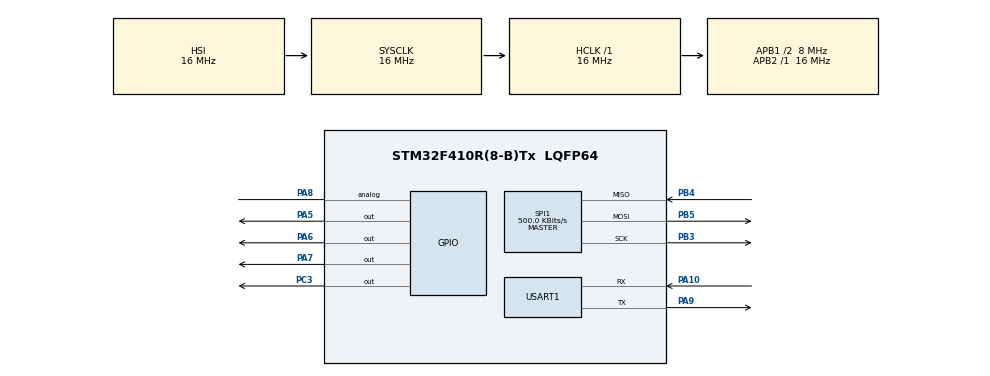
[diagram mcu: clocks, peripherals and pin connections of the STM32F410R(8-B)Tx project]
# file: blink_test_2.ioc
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Mcu.Family=STM32F4
Mcu.Name=STM32F410R(8-B)Tx
Mcu.Package=LQFP64
NVIC.PriorityGroup=NVIC_PRIORITYGROUP_4
NVIC.USART1_IRQn=true\:0\:0\:false\:false\:true\:true
PA10.Mode=Asynchronous
PA10.Signal=USART1_RX
PA5.Signal=GPIO_Output
PA6.Signal=GPIO_Output
PA7.Signal=GPIO_Output
PA8.Signal=GPIO_Analog
PA9.Mode=Asynchronous
PA9.Signal=USART1_TX
PB3.Mode=Full_Duplex_Master
PB3.Signal=SPI1_SCK
PB4.Mode=Full_Duplex_Master
PB4.Signal=SPI1_MISO
PB5.Mode=Full_Duplex_Master
PB5.Signal=SPI1_MOSI
PC3.Signal=GPIO_Output
ProjectManager.HeapSize=0x200
ProjectManager.StackSize=0x400
ProjectManager.TargetToolchain=MDK-ARM V5
RCC.48MHZClocksFreq_Value=84000000
RCC.AHBFreq_Value=16000000
RCC.APB1CLKDivider=RCC_HCLK_DIV2
RCC.APB1Freq_Value=8000000
RCC.APB1TimFreq_Value=16000000
RCC.APB2Freq_Value=16000000
RCC.APB2TimFreq_Value=16000000
RCC.CortexFreq_Value=16000000
RCC.FLatency-AdvancedSettings=FLASH_LATENCY_0
RCC.HCLKFreq_Value=16000000
RCC.HSE_VALUE=8000000
RCC.HSI_VALUE=16000000
RCC.LSE_VALUE=32768
RCC.PLLN=336
RCC.PLLP=RCC_PLLP_DIV4
RCC.SYSCLKFreq_VALUE=16000000
RCC.VCOOutputFreq_Value=336000000
SPI1.BaudRatePrescaler=SPI_BAUDRATEPRESCALER_32
SPI1.CalculateBaudRate=500.0 KBits/s
SPI1.Direction=SPI_DIRECTION_2LINES
SPI1.Mode=SPI_MODE_MASTER
SPI1.VirtualType=VM_MASTER
USART1.VirtualMode=VM_ASYNC
board=NUCLEO-F410RB

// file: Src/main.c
/**
  ******************************************************************************
  * @file           : main.c
  * @brief          : Main program body
  ******************************************************************************
  ** This notice applies to any and all portions of this file
  * that are not between comment pairs USER CODE BEGIN and
  * USER CODE END. Other portions of this file, whether
  * inserted by the user or by software development tools
  * are owned by their respective copyright owners.
  *
  * COPYRIGHT(c) 2018 STMicroelectronics
  *
  * Redistribution and use in source and binary forms, with or without modification,
  * are permitted provided that the following conditions are met:
  *   1. Redistributions of source code must retain the above copyright notice,
  *      this list of conditions and the following disclaimer.
  *   2. Redistributions in binary form must reproduce the above copyright notice,
  *      this list of conditions and the following disclaimer in the documentation
  *      and/or other materials provided with the distribution.
  *   3. Neither the name of STMicroelectronics nor the names of its contributors
  *      may be used to endorse or promote products derived from this software
  *      without specific prior written permission.
  *
  * THIS SOFTWARE IS PROVIDED BY THE COPYRIGHT HOLDERS AND CONTRIBUTORS "AS IS"
  * AND ANY EXPRESS OR IMPLIED WARRANTIES, INCLUDING, BUT NOT LIMITED TO, THE
  * IMPLIED WARRANTIES OF MERCHANTABILITY AND FITNESS FOR A PARTICULAR PURPOSE ARE
  * DISCLAIMED. IN NO EVENT SHALL THE COPYRIGHT HOLDER OR CONTRIBUTORS BE LIABLE
  * FOR ANY DIRECT, INDIRECT, INCIDENTAL, SPECIAL, EXEMPLARY, OR CONSEQUENTIAL
  * DAMAGES (INCLUDING, BUT NOT LIMITED TO, PROCUREMENT OF SUBSTITUTE GOODS OR
  * SERVICES; LOSS OF USE, DATA, OR PROFITS; OR BUSINESS INTERRUPTION) HOWEVER
  * CAUSED AND ON ANY THEORY OF LIABILITY, WHETHER IN CONTRACT, STRICT LIABILITY,
  * OR TORT (INCLUDING NEGLIGENCE OR OTHERWISE) ARISING IN ANY WAY OUT OF THE USE
  * OF THIS SOFTWARE, EVEN IF ADVISED OF THE POSSIBILITY OF SUCH DAMAGE.
  *
  ******************************************************************************
  */
#include "main.h"
#include "stm32f4xx_hal.h"

/* USER CODE BEGIN Includes */

#include "St_main.h"

/* USER CODE END Includes */

SPI_HandleTypeDef hspi1;

UART_HandleTypeDef huart1;

/* USER CODE BEGIN PV */
/* Private variables ---------------------------------------------------------*/

/* USER CODE END PV */

void SystemClock_Config(void);
static void MX_GPIO_Init(void);
static void MX_USART1_UART_Init(void);
static void MX_SPI1_Init(void);

/* USER CODE BEGIN PFP */
/* Private function prototypes -----------------------------------------------*/

/* USER CODE END PFP */

int main(void)
{

  /* MCU Configuration----------------------------------------------------------*/

  /* Reset of all peripherals, Initializes the Flash interface and the Systick. */
  HAL_Init();

  /* Configure the system clock */
  SystemClock_Config();

  /* Initialize all configured peripherals */
  MX_GPIO_Init();
  MX_USART1_UART_Init();
  MX_SPI1_Init();
  /* USER CODE BEGIN 2 */

	InitStMain(&huart1, &hspi1);

  /* USER CODE END 2 */

  /* Infinite loop */
  /* USER CODE BEGIN WHILE */
  while (1)
  {

		UpdateStMain();

  /* USER CODE END WHILE */

  }

}

void SystemClock_Config(void)
{

  RCC_OscInitTypeDef RCC_OscInitStruct;
  RCC_ClkInitTypeDef RCC_ClkInitStruct;

    /**Configure the main internal regulator output voltage
    */
  __HAL_RCC_PWR_CLK_ENABLE();

  __HAL_PWR_VOLTAGESCALING_CONFIG(PWR_REGULATOR_VOLTAGE_SCALE1);

    /**Initializes the CPU, AHB and APB busses clocks
    */
  RCC_OscInitStruct.OscillatorType = RCC_OSCILLATORTYPE_HSI;
  RCC_OscInitStruct.HSIState = RCC_HSI_ON;
  RCC_OscInitStruct.HSICalibrationValue = 16;
  RCC_OscInitStruct.PLL.PLLState = RCC_PLL_NONE;
  if (HAL_RCC_OscConfig(&RCC_OscInitStruct) != HAL_OK)
  {
    _Error_Handler(__FILE__, __LINE__);
  }

    /**Initializes the CPU, AHB and APB busses clocks
    */
  RCC_ClkInitStruct.ClockType = RCC_CLOCKTYPE_HCLK|RCC_CLOCKTYPE_SYSCLK
                              |RCC_CLOCKTYPE_PCLK1|RCC_CLOCKTYPE_PCLK2;
  RCC_ClkInitStruct.SYSCLKSource = RCC_SYSCLKSOURCE_HSI;
  RCC_ClkInitStruct.AHBCLKDivider = RCC_SYSCLK_DIV1;
  RCC_ClkInitStruct.APB1CLKDivider = RCC_HCLK_DIV2;
  RCC_ClkInitStruct.APB2CLKDivider = RCC_HCLK_DIV1;

  if (HAL_RCC_ClockConfig(&RCC_ClkInitStruct, FLASH_LATENCY_0) != HAL_OK)
  {
    _Error_Handler(__FILE__, __LINE__);
  }

    /**Configure the Systick interrupt time
    */
  HAL_SYSTICK_Config(HAL_RCC_GetHCLKFreq()/1000);

    /**Configure the Systick
    */
  HAL_SYSTICK_CLKSourceConfig(SYSTICK_CLKSOURCE_HCLK);

  /* SysTick_IRQn interrupt configuration */
  HAL_NVIC_SetPriority(SysTick_IRQn, 0, 0);
}

/* SPI1 init function */
static void MX_SPI1_Init(void)
{

  /* SPI1 parameter configuration*/
  hspi1.Instance = SPI1;
  hspi1.Init.Mode = SPI_MODE_MASTER;
  hspi1.Init.Direction = SPI_DIRECTION_2LINES;
  hspi1.Init.DataSize = SPI_DATASIZE_8BIT;
  hspi1.Init.CLKPolarity = SPI_POLARITY_LOW;
  hspi1.Init.CLKPhase = SPI_PHASE_1EDGE;
  hspi1.Init.NSS = SPI_NSS_SOFT;
  hspi1.Init.BaudRatePrescaler = SPI_BAUDRATEPRESCALER_32;
  hspi1.Init.FirstBit = SPI_FIRSTBIT_MSB;
  hspi1.Init.TIMode = SPI_TIMODE_DISABLE;
  hspi1.Init.CRCCalculation = SPI_CRCCALCULATION_DISABLE;
  hspi1.Init.CRCPolynomial = 15;
  if (HAL_SPI_Init(&hspi1) != HAL_OK)
  {
    _Error_Handler(__FILE__, __LINE__);
  }

}

/* USART1 init function */
static void MX_USART1_UART_Init(void)
{

  huart1.Instance = USART1;
  huart1.Init.BaudRate = 115200;
  huart1.Init.WordLength = UART_WORDLENGTH_8B;
  huart1.Init.StopBits = UART_STOPBITS_1;
  huart1.Init.Parity = UART_PARITY_NONE;
  huart1.Init.Mode = UART_MODE_TX_RX;
  huart1.Init.HwFlowCtl = UART_HWCONTROL_NONE;
  huart1.Init.OverSampling = UART_OVERSAMPLING_16;
  if (HAL_UART_Init(&huart1) != HAL_OK)
  {
    _Error_Handler(__FILE__, __LINE__);
  }

}

/** Configure pins as
        * Analog
        * Input
        * Output
        * EVENT_OUT
        * EXTI
*/
static void MX_GPIO_Init(void)
{

  GPIO_InitTypeDef GPIO_InitStruct;

  /* GPIO Ports Clock Enable */
  __HAL_RCC_GPIOC_CLK_ENABLE();
  __HAL_RCC_GPIOA_CLK_ENABLE();
  __HAL_RCC_GPIOB_CLK_ENABLE();

  /*Configure GPIO pin Output Level */
  HAL_GPIO_WritePin(GPIOC, GPIO_PIN_3, GPIO_PIN_RESET);

  /*Configure GPIO pin Output Level */
  HAL_GPIO_WritePin(GPIOA, GPIO_PIN_5|GPIO_PIN_6|GPIO_PIN_7, GPIO_PIN_RESET);

  /*Configure GPIO pin : PC3 */
  GPIO_InitStruct.Pin = GPIO_PIN_3;
  GPIO_InitStruct.Mode = GPIO_MODE_OUTPUT_PP;
  GPIO_InitStruct.Pull = GPIO_NOPULL;
  GPIO_InitStruct.Speed = GPIO_SPEED_FREQ_LOW;
  HAL_GPIO_Init(GPIOC, &GPIO_InitStruct);

  /*Configure GPIO pins : PA5 PA6 PA7 */
  GPIO_InitStruct.Pin = GPIO_PIN_5|GPIO_PIN_6|GPIO_PIN_7;
  GPIO_InitStruct.Mode = GPIO_MODE_OUTPUT_PP;
  GPIO_InitStruct.Pull = GPIO_NOPULL;
  GPIO_InitStruct.Speed = GPIO_SPEED_FREQ_LOW;
  HAL_GPIO_Init(GPIOA, &GPIO_InitStruct);

  /*Configure GPIO pin : PA8 */
  GPIO_InitStruct.Pin = GPIO_PIN_8;
  GPIO_InitStruct.Mode = GPIO_MODE_ANALOG;
  GPIO_InitStruct.Pull = GPIO_NOPULL;
  HAL_GPIO_Init(GPIOA, &GPIO_InitStruct);

}

void _Error_Handler(char *file, int line)
{
  while(1)
  {
  }
}

/************************ (C) COPYRIGHT STMicroelectronics *****END OF FILE****/
